# NPCX490M register map
File version: 1.0
Registers are 8-bit, read-write, reset 0x0 unless marked. A register's access mark holds for its fields unless they carry their own. Offsets are from the block's base; [hi:lo] are bit positions; {n}, {i} and the like mark numbered series.

## MTC
Base 0x400B7000
0x00 TTC 32-bit (reset mask 0xFF) — Timing Ticks Count Register (TTC)
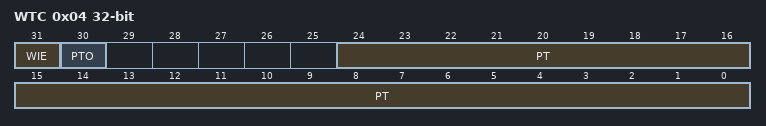
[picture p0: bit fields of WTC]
0x04 WTC 32-bit (reset mask 0xFF) — Wake-Up Ticks Count Register (WTC)
  [31] WIE — Wake-Up/Interrupt Enabled
  [30] PTO — Predefined Time Occurred
  [24:0] PT — Predefined Time

## OTPI
Base 0x40007000
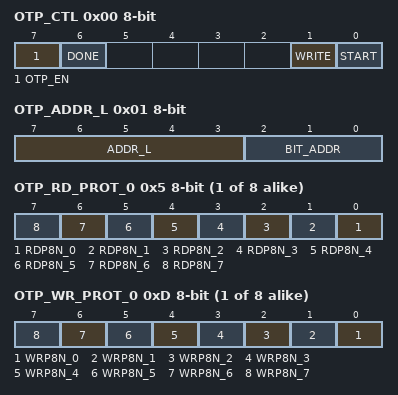
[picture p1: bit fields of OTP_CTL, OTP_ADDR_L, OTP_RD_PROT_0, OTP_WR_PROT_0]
0x00 OTP_CTL — OTP Control Register (OTP_CTL)
  [7] OTP_EN — OTPI Module Enable
  [6] DONE — OTP Operation Completed
  [1] WRITE — Write Select
  [0] START — Start OTP Operation
0x01 OTP_ADDR_L — OTP Address Low Register (OTP_ADDR_L)
  [7:3] ADDR_L — OTP Byte Address Low
  [2:0] BIT_ADDR — OTP Bit Address
0x02 OTP_ADDR_H — OTP Address High Register (OTP_ADDR_H)
  [5:0] ADDR_H — OTP Byte Address High
0x03 OTP_DOUT — OTP Read Data Register (OTP_DOUT)
{0x5+i} OTP_RD_PROT_{i} (i=0..7) — OTP Read Protect 0-15 Register (OTP_RD_PROT_0-15)
  [n] RDP8N_{n} (n=0..7) — Read Protect Block 8*n+{n}
{0xD+i} OTP_WR_PROT_{i} (i=0..7) — OTP Write Protect 0-15 Register (OTP_WR_PROT_0-15)
  [n] WRP8N_{n} (n=0..7) — Write Protect Block 8*n+{n}
0x15 OTP_PRESC — OTP Prescaler Register (OTP_PRESC)
{0x16+i} OTP_WRITE_EN{i} (i=0..3) — OTP Write Enable 0-3 Register (OTP_WRITE_EN0-3)
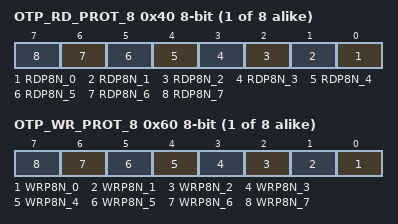
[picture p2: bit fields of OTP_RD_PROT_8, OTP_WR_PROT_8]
{0x38+i} OTP_RD_PROT_{i} (i=8..15) — OTP Read Protect 0-15 Register (OTP_RD_PROT_0-15)
  [n] RDP8N_{n} (n=0..7) — Read Protect Block 8*n+{n}
{0x58+i} OTP_WR_PROT_{i} (i=8..15) — OTP Write Protect 0-15 Register (OTP_WR_PROT_0-15)
  [n] WRP8N_{n} (n=0..7) — Write Protect Block 8*n+{n}

## PECI
Base 0x400D4000
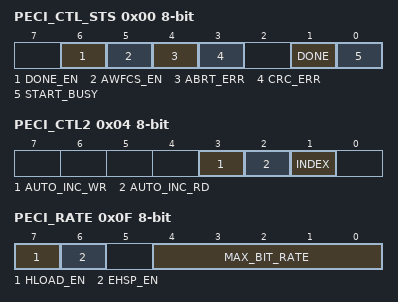
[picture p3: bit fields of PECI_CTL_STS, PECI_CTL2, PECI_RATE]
0x00 PECI_CTL_STS — PECI Control Status Register (PECI_CTL_STS)
  [6] DONE_EN — DONE Enable
  [5] AWFCS_EN — Assured Write FCS Enable
  [4] ABRT_ERR — Abort Error
  [3] CRC_ERR — CRC Error
  [1] DONE
  [0] START_BUSY
0x01 PECI_RD_LENGTH — PECI Read Length Register (PECI_RD_LENGTH)
  [6:0] READ_LENGTH
0x02 PECI_ADDR — PECI Address Register (PECI_ADDR)
0x03 PECI_CMD — PECI Command Register (PECI_CMD)
0x04 PECI_CTL2 — PECI Control 2 Register (PECI_CTL2)
  [3] AUTO_INC_WR — Automatic Increment on Write
  [2] AUTO_INC_RD — Automatic Increment on Read
  [1] INDEX
0x05 PECI_INDEX — PECI Index Register (PECI_INDEX)
  [5:0] DATA_INDEX
0x06 PECI_IDATA — PECI Index Data Registers (PECI_IDATA)
0x07 PECI_WR_LENGTH — PECI Write Length Register (PECI_WR_LENGTH)
  [6:0] WRITE_LENGTH
0x0B PECI_WR_FCS — PECI Write FCS Register (PECI_WR_FCS)
0x0C PECI_RD_FCS — PECI Read FCS Register (PECI_RD_FCS)
0x0D PECI_AW_FCS — PECI Assured Write FCS Register (PECI_AW_FCS)
0x0F PECI_RATE — PECI Transfer Rate Register (PECI_RATE)
  [7] HLOAD_EN — PECI High Load Enable
  [6] EHSP_EN — Enhanced High-Speed Enable
  [4:0] MAX_BIT_RATE — Maximum Bit Rate
{0x10+i} PECI_DATA_IN{i} (i=0..63) — PECI Data In Register (PECI_DATA_IN00-3F)
{0x10+i} PECI_DATA_OUT{i} (i=0..63) — PECI Data Out Register (PECI_DATA_OUT00-3F)

## PM1
Base 0x400C9000
Same registers: PM2 0x400CB000, PM3 0x400CD000, PM4 0x400CF000
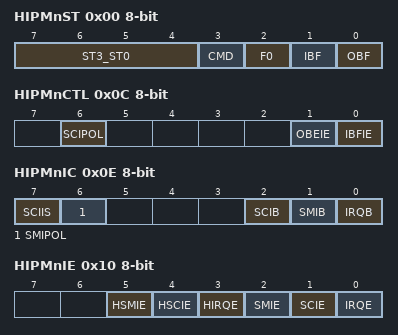
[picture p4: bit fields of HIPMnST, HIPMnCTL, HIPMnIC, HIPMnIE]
0x00 HIPMnST — Host Interface PM n Status Register (HIPMnST)
  [7:4] ST3_ST0 — Status
  [3] CMD — Command Register
  [2] F0 — Flag 0
  [1] IBF — Input Buffer Full
  [0] OBF — Output Buffer Full
0x02 HIPMnDO — Host Interface PM n Data Out Buffer Register (HIPMnDO)
0x04 HIPMnDI — Host Interface PM n Data In Buffer Register (HIPMnDI)
0x05 SHIPMnDI — Host Interface PM n Shadow Data In Buffer Register (SHIPMnDI)
0x06 HIPMnDOC — Host Interface PM n Data Out Buffer with SCI Register (HIPMnDOC)
0x08 HIPMnDOM — Host Interface PM n Data Out Buffer with SMI Register (HIPMnDOM)
0x0A HIPMnDIC — Host Interface PM n Data In Buffer with SCI Register (HIPMnDIC)
0x0C HIPMnCTL — Host Interface PM n Control Register (HIPMnCTL)
  [6] SCIPOL — SCI Negative Polarity
  [1] OBEIE — Output Buffer Empty Interrupt Enable
  [0] IBFIE — Input Buffer Full Interrupt Enable
0x0D HIPMnCTL2 — Host Interface PM n Control 2 Register (HIPMnCTL2)
  [1] FW_OBF — Firmware Control Over OBF
0x0E HIPMnIC — Host Interface PM n Interrupt Control Register (HIPMnIC)
  [7] SCIIS — SCI on IBF Start
  [6] SMIPOL — SMI Negative Polarity
  [2] SCIB — Host SCI Request Control Bit
  [1] SMIB — Host SMI Request Control Bit
  [0] IRQB — Host Interrupt Request Control Bit
0x10 HIPMnIE — Host Interface PM n Interrupt Enable Register (HIPMnIE)
  [5] HSMIE — Hardware SMI Enable
  [4] HSCIE — Hardware SCI Enable
  [3] HIRQE — Hardware IRQ Enable
  [2] SMIE — SMI Enable
  [1] SCIE — SCI Enable
  [0] IRQE — IRQ Enable
